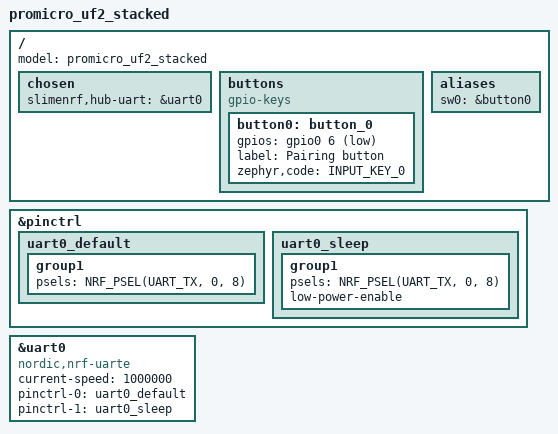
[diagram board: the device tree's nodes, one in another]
// Stacked ProMicro (tracker build) used as a receiver for the ESP32 hub.
// SPDX-License-Identifier: Apache-2.0

/dts-v1/;
#include "promicro_uf2.dts"
#include <zephyr/dt-bindings/input/input-event-codes.h>

&pinctrl {
	uart0_default: uart0_default {
		group1 {
			psels = <NRF_PSEL(UART_TX, 0, 8)>;
		};
	};

	uart0_sleep: uart0_sleep {
		group1 {
			psels = <NRF_PSEL(UART_TX, 0, 8)>;
			low-power-enable;
		};
	};
};

/ {
	model = "promicro_uf2_stacked";

	chosen {
		slimenrf,hub-uart = &uart0;
	};

	buttons {
		compatible = "gpio-keys";
		button0: button_0 {
			gpios = <&gpio0 6 (GPIO_PULL_UP | GPIO_ACTIVE_LOW)>;
			label = "Pairing button";
			zephyr,code = <INPUT_KEY_0>;
		};
	};

	aliases {
		sw0 = &button0;
	};
};

// TX only, on P0.08 (D0) to the hub's RX pin. P0.08 is a full-speed pin; P0.29 and the
// other "low frequency I/O only" pins are avoided because a UART there while the radio
// is active can increase packet loss (nRF52840 PS, pin assignments).
// The stacked build's IMU, SPI and power pins (P0.02, P0.11, P0.17, P0.20, P0.22, P0.24,
// P1.00, P1.11) are left untouched.
&uart0 {
	compatible = "nordic,nrf-uarte";
	status = "okay";
	current-speed = <1000000>;
	pinctrl-0 = <&uart0_default>;
	pinctrl-1 = <&uart0_sleep>;
	pinctrl-names = "default", "sleep";
};
